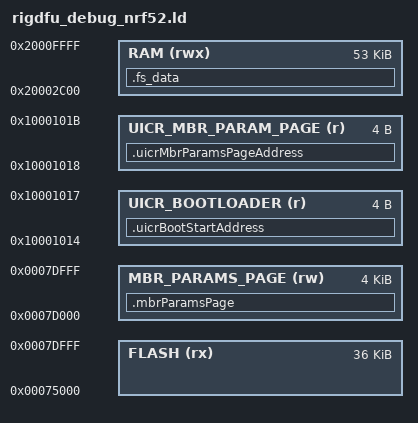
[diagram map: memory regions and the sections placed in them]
/* Linker script to configure memory regions. */

SEARCH_DIR(.)
GROUP(-lgcc -lc -lnosys)

MEMORY
{
  FLASH (rx) : ORIGIN = 0x75000, LENGTH = 0x9000
  RAM (rwx) :  ORIGIN = 0x20002C00, LENGTH = 0xD400

  UICR_BOOTLOADER (r) : ORIGIN = 0x10001014, LENGTH = 0x04

  MBR_PARAMS_PAGE (rw) : ORIGIN = 0x0007D000, LENGTH = 0x1000
  UICR_MBR_PARAM_PAGE(r) : ORIGIN = 0x10001018, LENGTH = 0x04
}

SECTIONS
{
  .fs_data :
  {
    PROVIDE(__start_fs_data = .);
    KEEP(*(.fs_data))
    PROVIDE(__stop_fs_data = .);
  } > RAM

  /* Write the bootloader address in UICR. */
  .uicrBootStartAddress :
  {
    KEEP(*(.uicrBootStartAddress))
  } > UICR_BOOTLOADER

  /* Place the mbr params page in flash. */
  .mbrParamsPage(NOLOAD) :
  {

  } > MBR_PARAMS_PAGE

  /* Write the bootloader address in UICR. */
  .uicrMbrParamsPageAddress :
  {
    KEEP(*(.uicrMbrParamsPageAddress))
  } > UICR_MBR_PARAM_PAGE

} INSERT AFTER .data;

SECTIONS
{
  .mem_section_dummy_rom :
  {
  }
  .log_const_data :
  {
    PROVIDE(__start_log_const_data = .);
    KEEP(*(SORT(.log_const_data*)))
    PROVIDE(__stop_log_const_data = .);
  } > FLASH
  .sdh_ble_observers :
  {
    PROVIDE(__start_sdh_ble_observers = .);
    KEEP(*(SORT(.sdh_ble_observers*)))
    PROVIDE(__stop_sdh_ble_observers = .);
  } > FLASH
  .sdh_req_observers :
  {
    PROVIDE(__start_sdh_req_observers = .);
    KEEP(*(SORT(.sdh_req_observers*)))
    PROVIDE(__stop_sdh_req_observers = .);
  } > FLASH
  .sdh_state_observers :
  {
    PROVIDE(__start_sdh_state_observers = .);
    KEEP(*(SORT(.sdh_state_observers*)))
    PROVIDE(__stop_sdh_state_observers = .);
  } > FLASH
  .sdh_stack_observers :
  {
    PROVIDE(__start_sdh_stack_observers = .);
    KEEP(*(SORT(.sdh_stack_observers*)))
    PROVIDE(__stop_sdh_stack_observers = .);
  } > FLASH
  .sdh_soc_observers :
  {
    PROVIDE(__start_sdh_soc_observers = .);
    KEEP(*(SORT(.sdh_soc_observers*)))
    PROVIDE(__stop_sdh_soc_observers = .);
  } > FLASH
  

} INSERT AFTER .text

SECTIONS
{
  . = ALIGN(4);
  .mem_section_dummy_ram :
  {
  }
  .log_dynamic_data :
  {
    PROVIDE(__start_log_dynamic_data = .);
    KEEP(*(SORT(.log_dynamic_data*)))
    PROVIDE(__stop_log_dynamic_data = .);
  } > RAM
  .fs_data :
  {
    PROVIDE(__start_fs_data = .);
    KEEP(*(.fs_data))
    PROVIDE(__stop_fs_data = .);
  } > RAM

} INSERT AFTER .data;

INCLUDE "nrf5x_common.ld"
